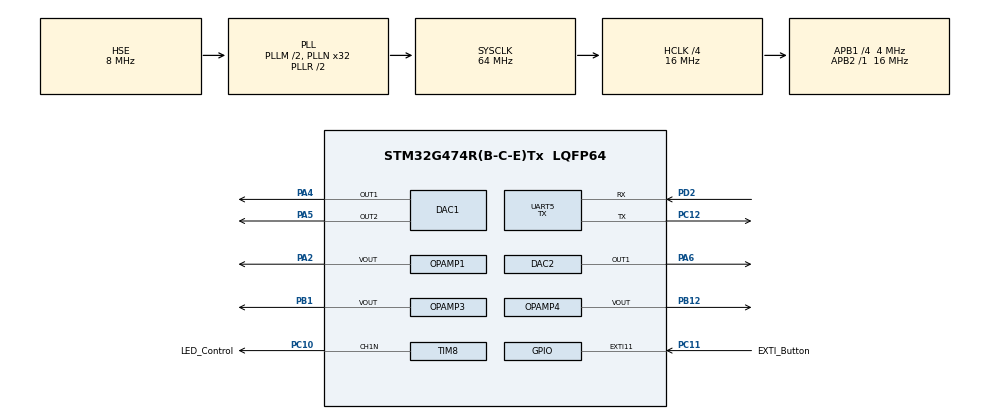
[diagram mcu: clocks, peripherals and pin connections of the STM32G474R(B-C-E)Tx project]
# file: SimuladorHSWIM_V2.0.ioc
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DAC1.DAC_Channel-DAC_OUT2=DAC_CHANNEL_2
DAC1.DAC_Trigger2_OUT1-DAC_OUT1=DAC_TRIGGER_NONE
DAC1.DAC_Trigger2_OUT2-DAC_OUT2=DAC_TRIGGER_NONE
DAC1.DAC_Trigger_OUT1-DAC_OUT1=DAC_TRIGGER_T2_TRGO
DAC1.DAC_Trigger_OUT2-DAC_OUT2=DAC_TRIGGER_T2_TRGO
DAC2.DAC_Trigger_OUT1-DAC_OUT1=DAC_TRIGGER_T2_TRGO
DAC3.DAC_Channel-DAC_OUT2_Int=DAC_CHANNEL_2
DAC3.DAC_Trigger_OUT1-DAC_OUT1_Int=DAC_TRIGGER_T2_TRGO
DAC3.DAC_Trigger_OUT2-DAC_OUT2_Int=DAC_TRIGGER_T2_TRGO
DAC4.DAC_Trigger_OUT1-DAC_OUT1_Int=DAC_TRIGGER_T2_TRGO
Dma.DAC1_CH1.0.Direction=DMA_MEMORY_TO_PERIPH
Dma.DAC1_CH1.0.EventEnable=DISABLE
Dma.DAC1_CH1.0.Instance=DMA1_Channel1
Dma.DAC1_CH1.0.MemDataAlignment=DMA_MDATAALIGN_WORD
Dma.DAC1_CH1.0.MemInc=DMA_MINC_ENABLE
Dma.DAC1_CH1.0.Mode=DMA_NORMAL
Dma.DAC1_CH1.0.PeriphDataAlignment=DMA_PDATAALIGN_WORD
Dma.DAC1_CH1.0.PeriphInc=DMA_PINC_DISABLE
Dma.DAC1_CH1.0.Polarity=HAL_DMAMUX_REQ_GEN_RISING
Dma.DAC1_CH1.0.Priority=DMA_PRIORITY_LOW
Dma.DAC1_CH1.0.RequestNumber=1
Dma.DAC1_CH1.0.SignalID=NONE
Dma.DAC1_CH1.0.SyncEnable=DISABLE
Dma.DAC1_CH1.0.SyncPolarity=HAL_DMAMUX_SYNC_NO_EVENT
Dma.DAC1_CH1.0.SyncRequestNumber=1
Dma.DAC1_CH1.0.SyncSignalID=NONE
Dma.DAC1_CH2.1.Direction=DMA_MEMORY_TO_PERIPH
Dma.DAC1_CH2.1.EventEnable=DISABLE
Dma.DAC1_CH2.1.Instance=DMA1_Channel2
Dma.DAC1_CH2.1.MemDataAlignment=DMA_MDATAALIGN_WORD
Dma.DAC1_CH2.1.MemInc=DMA_MINC_ENABLE
Dma.DAC1_CH2.1.Mode=DMA_NORMAL
Dma.DAC1_CH2.1.PeriphDataAlignment=DMA_PDATAALIGN_WORD
Dma.DAC1_CH2.1.PeriphInc=DMA_PINC_DISABLE
Dma.DAC1_CH2.1.Polarity=HAL_DMAMUX_REQ_GEN_RISING
Dma.DAC1_CH2.1.Priority=DMA_PRIORITY_LOW
Dma.DAC1_CH2.1.RequestNumber=1
Dma.DAC1_CH2.1.SignalID=NONE
Dma.DAC1_CH2.1.SyncEnable=DISABLE
Dma.DAC1_CH2.1.SyncPolarity=HAL_DMAMUX_SYNC_NO_EVENT
Dma.DAC1_CH2.1.SyncRequestNumber=1
Dma.DAC1_CH2.1.SyncSignalID=NONE
Dma.DAC2_CH1.2.Direction=DMA_MEMORY_TO_PERIPH
Dma.DAC2_CH1.2.EventEnable=DISABLE
Dma.DAC2_CH1.2.Instance=DMA1_Channel3
Dma.DAC2_CH1.2.MemDataAlignment=DMA_MDATAALIGN_WORD
Dma.DAC2_CH1.2.MemInc=DMA_MINC_ENABLE
Dma.DAC2_CH1.2.Mode=DMA_NORMAL
Dma.DAC2_CH1.2.PeriphDataAlignment=DMA_PDATAALIGN_WORD
Dma.DAC2_CH1.2.PeriphInc=DMA_PINC_DISABLE
Dma.DAC2_CH1.2.Polarity=HAL_DMAMUX_REQ_GEN_RISING
Dma.DAC2_CH1.2.Priority=DMA_PRIORITY_LOW
Dma.DAC2_CH1.2.RequestNumber=1
Dma.DAC2_CH1.2.SignalID=NONE
Dma.DAC2_CH1.2.SyncEnable=DISABLE
Dma.DAC2_CH1.2.SyncPolarity=HAL_DMAMUX_SYNC_NO_EVENT
Dma.DAC2_CH1.2.SyncRequestNumber=1
Dma.DAC2_CH1.2.SyncSignalID=NONE
Dma.DAC3_CH1.3.Direction=DMA_MEMORY_TO_PERIPH
Dma.DAC3_CH1.3.EventEnable=DISABLE
Dma.DAC3_CH1.3.Instance=DMA1_Channel4
Dma.DAC3_CH1.3.MemDataAlignment=DMA_MDATAALIGN_WORD
Dma.DAC3_CH1.3.MemInc=DMA_MINC_ENABLE
Dma.DAC3_CH1.3.Mode=DMA_NORMAL
Dma.DAC3_CH1.3.PeriphDataAlignment=DMA_PDATAALIGN_WORD
Dma.DAC3_CH1.3.PeriphInc=DMA_PINC_DISABLE
Dma.DAC3_CH1.3.Polarity=HAL_DMAMUX_REQ_GEN_RISING
Dma.DAC3_CH1.3.Priority=DMA_PRIORITY_LOW
Dma.DAC3_CH1.3.RequestNumber=1
Dma.DAC3_CH1.3.SignalID=NONE
Dma.DAC3_CH1.3.SyncEnable=DISABLE
Dma.DAC3_CH1.3.SyncPolarity=HAL_DMAMUX_SYNC_NO_EVENT
Dma.DAC3_CH1.3.SyncRequestNumber=1
Dma.DAC3_CH1.3.SyncSignalID=NONE
Dma.DAC3_CH2.4.Direction=DMA_MEMORY_TO_PERIPH
Dma.DAC3_CH2.4.EventEnable=DISABLE
Dma.DAC3_CH2.4.Instance=DMA1_Channel5
Dma.DAC3_CH2.4.MemDataAlignment=DMA_MDATAALIGN_WORD
Dma.DAC3_CH2.4.MemInc=DMA_MINC_ENABLE
Dma.DAC3_CH2.4.Mode=DMA_NORMAL
Dma.DAC3_CH2.4.PeriphDataAlignment=DMA_PDATAALIGN_WORD
Dma.DAC3_CH2.4.PeriphInc=DMA_PINC_DISABLE
Dma.DAC3_CH2.4.Polarity=HAL_DMAMUX_REQ_GEN_RISING
Dma.DAC3_CH2.4.Priority=DMA_PRIORITY_LOW
Dma.DAC3_CH2.4.RequestNumber=1
Dma.DAC3_CH2.4.SignalID=NONE
Dma.DAC3_CH2.4.SyncEnable=DISABLE
Dma.DAC3_CH2.4.SyncPolarity=HAL_DMAMUX_SYNC_NO_EVENT
Dma.DAC3_CH2.4.SyncRequestNumber=1
Dma.DAC3_CH2.4.SyncSignalID=NONE
Dma.DAC4_CH1.5.Direction=DMA_MEMORY_TO_PERIPH
Dma.DAC4_CH1.5.EventEnable=DISABLE
Dma.DAC4_CH1.5.Instance=DMA1_Channel6
Dma.DAC4_CH1.5.MemDataAlignment=DMA_MDATAALIGN_WORD
Dma.DAC4_CH1.5.MemInc=DMA_MINC_ENABLE
Dma.DAC4_CH1.5.Mode=DMA_NORMAL
Dma.DAC4_CH1.5.PeriphDataAlignment=DMA_PDATAALIGN_WORD
Dma.DAC4_CH1.5.PeriphInc=DMA_PINC_DISABLE
Dma.DAC4_CH1.5.Polarity=HAL_DMAMUX_REQ_GEN_RISING
Dma.DAC4_CH1.5.Priority=DMA_PRIORITY_LOW
Dma.DAC4_CH1.5.RequestNumber=1
Dma.DAC4_CH1.5.SignalID=NONE
Dma.DAC4_CH1.5.SyncEnable=DISABLE
Dma.DAC4_CH1.5.SyncPolarity=HAL_DMAMUX_SYNC_NO_EVENT
Dma.DAC4_CH1.5.SyncRequestNumber=1
Dma.DAC4_CH1.5.SyncSignalID=NONE
Dma.Request0=DAC1_CH1
Dma.Request1=DAC1_CH2
Dma.Request2=DAC2_CH1
Dma.Request3=DAC3_CH1
Dma.Request4=DAC3_CH2
Dma.Request5=DAC4_CH1
Mcu.Family=STM32G4
Mcu.Name=STM32G474R(B-C-E)Tx
Mcu.Package=LQFP64
NVIC.DMA1_Channel1_IRQn=true\:0\:0\:false\:false\:true\:false\:true\:true
NVIC.DMA1_Channel2_IRQn=true\:0\:0\:false\:false\:true\:false\:true\:true
NVIC.DMA1_Channel3_IRQn=true\:0\:0\:false\:false\:true\:false\:true\:true
NVIC.DMA1_Channel4_IRQn=true\:0\:0\:false\:false\:true\:false\:true\:true
NVIC.DMA1_Channel5_IRQn=true\:0\:0\:false\:false\:true\:false\:true\:true
NVIC.DMA1_Channel6_IRQn=true\:0\:0\:false\:false\:true\:false\:true\:true
NVIC.EXTI15_10_IRQn=true\:0\:0\:false\:false\:true\:true\:true\:true
NVIC.PriorityGroup=NVIC_PRIORITYGROUP_4
NVIC.TIM3_IRQn=true\:0\:0\:false\:false\:true\:true\:true\:true
OPAMP1.PowerMode=OPAMP_POWERMODE_HIGHSPEED
OPAMP3.PowerMode=OPAMP_POWERMODE_HIGHSPEED
OPAMP4.PowerMode=OPAMP_POWERMODE_HIGHSPEED
PA13.Mode=Trace_Asynchronous_SW
PA13.Signal=SYS_JTMS-SWDIO
PA14.Mode=Trace_Asynchronous_SW
PA14.Signal=SYS_JTCK-SWCLK
PA2.Signal=SharedAnalog_PA2
PA4.Signal=COMP_DAC11_group
PA5.Signal=COMP_DAC12_group
PA6.Signal=COMP_DAC21_group
PB1.Signal=SharedAnalog_PB1
PB12.Signal=SharedAnalog_PB12
PB3.Mode=Trace_Asynchronous_SW
PB3.Signal=SYS_JTDO-SWO
PC10.GPIO_Label=LED_Control
PC10.Mode=PWM Generation1 CH1N
PC10.Signal=TIM8_CH1N
PC11.GPIO_Label=EXTI_Button
PC11.GPIO_PuPd=GPIO_PULLDOWN
PC11.Signal=GPXTI11
PC12.Mode=Asynchronous
PC12.Signal=UART5_TX
PD2.Mode=Asynchronous
PD2.Signal=UART5_RX
PF0-OSC_IN.Mode=HSE-External-Oscillator
PF0-OSC_IN.Signal=RCC_OSC_IN
PF1-OSC_OUT.Mode=HSE-External-Oscillator
PF1-OSC_OUT.Signal=RCC_OSC_OUT
ProjectManager.HeapSize=0x200
ProjectManager.StackSize=0x400
ProjectManager.TargetToolchain=STM32CubeIDE
RCC.ADC12Freq_Value=64000000
RCC.ADC345Freq_Value=64000000
RCC.AHBCLKDivider=RCC_SYSCLK_DIV4
RCC.AHBFreq_Value=16000000
RCC.APB1CLKDivider=RCC_HCLK_DIV4
RCC.APB1Freq_Value=4000000
RCC.APB1TimFreq_Value=8000000
RCC.APB2Freq_Value=16000000
RCC.APB2TimFreq_Value=16000000
RCC.CortexFreq_Value=16000000
RCC.EXTERNAL_CLOCK_VALUE=12288000
RCC.HCLKFreq_Value=16000000
RCC.HSE_VALUE=8000000
RCC.HSI48_VALUE=48000000
RCC.HSI_VALUE=16000000
RCC.LSE_VALUE=32768
RCC.PLLM=RCC_PLLM_DIV2
RCC.PLLN=32
RCC.PLLSourceVirtual=RCC_PLLSOURCE_HSE
RCC.PREFETCH_ENABLE=1
RCC.PWREXT_OverDrive=PWREXT_OverDrive_DESACTIVATED
RCC.PWR_Regulator_Voltage_Scale=PWR_REGULATOR_VOLTAGE_SCALE1
RCC.RCC_TIM_PRescaler_Selection=RCC_TIMPRES_DESACTIVATED
RCC.SYSCLKFreq_VALUE=64000000
RCC.SYSCLKSource=RCC_SYSCLKSOURCE_PLLCLK
RCC.USBFreq_Value=64000000
RCC.VCOOutputFreq_Value=128000000
SH.COMP_DAC11_group.0=DAC1_OUT1,DAC_OUT1
SH.COMP_DAC12_group.0=DAC1_OUT2,DAC_OUT2
SH.COMP_DAC21_group.0=DAC2_OUT1,DAC_OUT1
SH.SharedAnalog_PA2.0=GPIO_Analog
SH.SharedAnalog_PA2.1=OPAMP1_VOUT,Follower-DAC_OUT2-INP
SH.SharedAnalog_PB1.0=GPIO_Analog
SH.SharedAnalog_PB1.1=OPAMP3_VOUT,Follower-DAC_OUT2-INP
SH.SharedAnalog_PB12.0=GPIO_Analog
SH.SharedAnalog_PB12.1=OPAMP4_VOUT,Follower-DAC_OUT2-INP
TIM2.PeriodNoDither=52.0833-1
TIM2.Prescaler=32-1
TIM2.TIM_MasterOutputTrigger=TIM_TRGO_UPDATE
TIM3.PeriodNoDither=3000-1
TIM3.Prescaler=16000-1
TIM8.BreakPolarity=TIM_BREAKPOLARITY_LOW
TIM8.Channel-PWM\ Generation1\ CH1N=TIM_CHANNEL_1
TIM8.OC1Preload_PWM=DISABLE
TIM8.OCMode_PWM-PWM\ Generation1\ CH1N=TIM_OCMODE_PWM1
TIM8.OCNPolarity_1=TIM_OCNPOLARITY_LOW
TIM8.PeriodNoDither=100
TIM8.Prescaler=16000
TIM8.PulseNoDither_1=50
TIM8.TIM_MasterOutputTrigger=TIM_TRGO_RESET
TIM8.TIM_MasterOutputTrigger2=TIM_TRGO2_RESET
UART5.Mode=MODE_TX
VP_DAC3_VS_DACI1.Mode=DAC_OUT1_Int
VP_DAC3_VS_DACI2.Mode=DAC_OUT2_Int
VP_DAC4_VS_DACI1.Mode=DAC_OUT1_Int
VP_SYS_VS_DBSignals.Mode=DisableDeadBatterySignals
VP_TIM2_VS_ClockSourceINT.Mode=Internal
VP_TIM3_VS_ClockSourceINT.Mode=Internal
VP_TIM8_VS_OPM.Mode=OPM_bit
board=custom

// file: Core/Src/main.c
/* USER CODE BEGIN Header */
/**
  ******************************************************************************
  * @file           : main.c
  * @brief          : Main program body
  ******************************************************************************
  * @attention
  *
  * Copyright (c) 2024 STMicroelectronics.
  * All rights reserved.
  *
  * This software is licensed under terms that can be found in the LICENSE file
  * in the root directory of this software component.
  * If no LICENSE file comes with this software, it is provided AS-IS.
  *
  ******************************************************************************
  */
/* USER CODE END Header */
#include "main.h"

/* USER CODE BEGIN Includes */
#include "DACSim.h"
/* USER CODE END Includes */

DAC_HandleTypeDef hdac1;
DAC_HandleTypeDef hdac2;
DAC_HandleTypeDef hdac3;
DAC_HandleTypeDef hdac4;
DMA_HandleTypeDef hdma_dac1_ch1;
DMA_HandleTypeDef hdma_dac1_ch2;
DMA_HandleTypeDef hdma_dac2_ch1;
DMA_HandleTypeDef hdma_dac3_ch1;
DMA_HandleTypeDef hdma_dac3_ch2;
DMA_HandleTypeDef hdma_dac4_ch1;

OPAMP_HandleTypeDef hopamp1;
OPAMP_HandleTypeDef hopamp3;
OPAMP_HandleTypeDef hopamp4;

TIM_HandleTypeDef htim2;
TIM_HandleTypeDef htim3;
TIM_HandleTypeDef htim8;

UART_HandleTypeDef huart5;

void SystemClock_Config(void);
static void MX_GPIO_Init(void);
static void MX_DMA_Init(void);
static void MX_DAC1_Init(void);
static void MX_DAC2_Init(void);
static void MX_DAC3_Init(void);
static void MX_OPAMP1_Init(void);
static void MX_OPAMP3_Init(void);
static void MX_TIM2_Init(void);
static void MX_DAC4_Init(void);
static void MX_OPAMP4_Init(void);
static void MX_TIM3_Init(void);
static void MX_UART5_Init(void);
static void MX_TIM8_Init(void);

int main(void)
{

  /* MCU Configuration--------------------------------------------------------*/

  /* Reset of all peripherals, Initializes the Flash interface and the Systick. */
  HAL_Init();

  /* Configure the system clock */
  SystemClock_Config();

  /* Initialize all configured peripherals */
  MX_GPIO_Init();
  MX_DMA_Init();
  MX_DAC1_Init();
  MX_DAC2_Init();
  MX_DAC3_Init();
  MX_OPAMP1_Init();
  MX_OPAMP3_Init();
  MX_TIM2_Init();
  MX_DAC4_Init();
  MX_OPAMP4_Init();
  MX_TIM3_Init();
  MX_UART5_Init();
  MX_TIM8_Init();
  /* USER CODE BEGIN 2 */

  SysInit();
  /* USER CODE END 2 */

  /* Infinite loop */
  while (1)
  {

    /* USER CODE BEGIN 3 */

	  LoopMain();
  }
  /* USER CODE END 3 */
}

void SystemClock_Config(void)
{
  RCC_OscInitTypeDef RCC_OscInitStruct = {0};
  RCC_ClkInitTypeDef RCC_ClkInitStruct = {0};

  /** Configure the main internal regulator output voltage
  */
  HAL_PWREx_ControlVoltageScaling(PWR_REGULATOR_VOLTAGE_SCALE1);

  /** Initializes the RCC Oscillators according to the specified parameters
  * in the RCC_OscInitTypeDef structure.
  */
  RCC_OscInitStruct.OscillatorType = RCC_OSCILLATORTYPE_HSE;
  RCC_OscInitStruct.HSEState = RCC_HSE_ON;
  RCC_OscInitStruct.PLL.PLLState = RCC_PLL_ON;
  RCC_OscInitStruct.PLL.PLLSource = RCC_PLLSOURCE_HSE;
  RCC_OscInitStruct.PLL.PLLM = RCC_PLLM_DIV2;
  RCC_OscInitStruct.PLL.PLLN = 32;
  RCC_OscInitStruct.PLL.PLLP = RCC_PLLP_DIV2;
  RCC_OscInitStruct.PLL.PLLQ = RCC_PLLQ_DIV2;
  RCC_OscInitStruct.PLL.PLLR = RCC_PLLR_DIV2;
  if (HAL_RCC_OscConfig(&RCC_OscInitStruct) != HAL_OK)
  {
    Error_Handler();
  }

  /** Initializes the CPU, AHB and APB buses clocks
  */
  RCC_ClkInitStruct.ClockType = RCC_CLOCKTYPE_HCLK|RCC_CLOCKTYPE_SYSCLK
                              |RCC_CLOCKTYPE_PCLK1|RCC_CLOCKTYPE_PCLK2;
  RCC_ClkInitStruct.SYSCLKSource = RCC_SYSCLKSOURCE_PLLCLK;
  RCC_ClkInitStruct.AHBCLKDivider = RCC_SYSCLK_DIV4;
  RCC_ClkInitStruct.APB1CLKDivider = RCC_HCLK_DIV4;
  RCC_ClkInitStruct.APB2CLKDivider = RCC_HCLK_DIV1;

  if (HAL_RCC_ClockConfig(&RCC_ClkInitStruct, FLASH_LATENCY_0) != HAL_OK)
  {
    Error_Handler();
  }
}

static void MX_DAC1_Init(void)
{

  DAC_ChannelConfTypeDef sConfig = {0};

  /** DAC Initialization
  */
  hdac1.Instance = DAC1;
  if (HAL_DAC_Init(&hdac1) != HAL_OK)
  {
    Error_Handler();
  }

  /** DAC channel OUT1 config
  */
  sConfig.DAC_HighFrequency = DAC_HIGH_FREQUENCY_INTERFACE_MODE_AUTOMATIC;
  sConfig.DAC_DMADoubleDataMode = DISABLE;
  sConfig.DAC_SignedFormat = DISABLE;
  sConfig.DAC_SampleAndHold = DAC_SAMPLEANDHOLD_DISABLE;
  sConfig.DAC_Trigger = DAC_TRIGGER_T2_TRGO;
  sConfig.DAC_Trigger2 = DAC_TRIGGER_NONE;
  sConfig.DAC_OutputBuffer = DAC_OUTPUTBUFFER_ENABLE;
  sConfig.DAC_ConnectOnChipPeripheral = DAC_CHIPCONNECT_EXTERNAL;
  sConfig.DAC_UserTrimming = DAC_TRIMMING_FACTORY;
  if (HAL_DAC_ConfigChannel(&hdac1, &sConfig, DAC_CHANNEL_1) != HAL_OK)
  {
    Error_Handler();
  }

  /** DAC channel OUT2 config
  */
  if (HAL_DAC_ConfigChannel(&hdac1, &sConfig, DAC_CHANNEL_2) != HAL_OK)
  {
    Error_Handler();
  }

}

static void MX_DAC2_Init(void)
{

  DAC_ChannelConfTypeDef sConfig = {0};

  /** DAC Initialization
  */
  hdac2.Instance = DAC2;
  if (HAL_DAC_Init(&hdac2) != HAL_OK)
  {
    Error_Handler();
  }

  /** DAC channel OUT1 config
  */
  sConfig.DAC_HighFrequency = DAC_HIGH_FREQUENCY_INTERFACE_MODE_AUTOMATIC;
  sConfig.DAC_DMADoubleDataMode = DISABLE;
  sConfig.DAC_SignedFormat = DISABLE;
  sConfig.DAC_SampleAndHold = DAC_SAMPLEANDHOLD_DISABLE;
  sConfig.DAC_Trigger = DAC_TRIGGER_T2_TRGO;
  sConfig.DAC_Trigger2 = DAC_TRIGGER_NONE;
  sConfig.DAC_OutputBuffer = DAC_OUTPUTBUFFER_ENABLE;
  sConfig.DAC_ConnectOnChipPeripheral = DAC_CHIPCONNECT_EXTERNAL;
  sConfig.DAC_UserTrimming = DAC_TRIMMING_FACTORY;
  if (HAL_DAC_ConfigChannel(&hdac2, &sConfig, DAC_CHANNEL_1) != HAL_OK)
  {
    Error_Handler();
  }

}

static void MX_DAC3_Init(void)
{

  DAC_ChannelConfTypeDef sConfig = {0};

  /** DAC Initialization
  */
  hdac3.Instance = DAC3;
  if (HAL_DAC_Init(&hdac3) != HAL_OK)
  {
    Error_Handler();
  }

  /** DAC channel OUT1 config
  */
  sConfig.DAC_HighFrequency = DAC_HIGH_FREQUENCY_INTERFACE_MODE_AUTOMATIC;
  sConfig.DAC_DMADoubleDataMode = DISABLE;
  sConfig.DAC_SignedFormat = DISABLE;
  sConfig.DAC_SampleAndHold = DAC_SAMPLEANDHOLD_DISABLE;
  sConfig.DAC_Trigger = DAC_TRIGGER_T2_TRGO;
  sConfig.DAC_Trigger2 = DAC_TRIGGER_NONE;
  sConfig.DAC_OutputBuffer = DAC_OUTPUTBUFFER_DISABLE;
  sConfig.DAC_ConnectOnChipPeripheral = DAC_CHIPCONNECT_INTERNAL;
  sConfig.DAC_UserTrimming = DAC_TRIMMING_FACTORY;
  if (HAL_DAC_ConfigChannel(&hdac3, &sConfig, DAC_CHANNEL_1) != HAL_OK)
  {
    Error_Handler();
  }

  /** DAC channel OUT2 config
  */
  if (HAL_DAC_ConfigChannel(&hdac3, &sConfig, DAC_CHANNEL_2) != HAL_OK)
  {
    Error_Handler();
  }

}

static void MX_DAC4_Init(void)
{

  DAC_ChannelConfTypeDef sConfig = {0};

  /** DAC Initialization
  */
  hdac4.Instance = DAC4;
  if (HAL_DAC_Init(&hdac4) != HAL_OK)
  {
    Error_Handler();
  }

  /** DAC channel OUT1 config
  */
  sConfig.DAC_HighFrequency = DAC_HIGH_FREQUENCY_INTERFACE_MODE_AUTOMATIC;
  sConfig.DAC_DMADoubleDataMode = DISABLE;
  sConfig.DAC_SignedFormat = DISABLE;
  sConfig.DAC_SampleAndHold = DAC_SAMPLEANDHOLD_DISABLE;
  sConfig.DAC_Trigger = DAC_TRIGGER_T2_TRGO;
  sConfig.DAC_Trigger2 = DAC_TRIGGER_NONE;
  sConfig.DAC_OutputBuffer = DAC_OUTPUTBUFFER_DISABLE;
  sConfig.DAC_ConnectOnChipPeripheral = DAC_CHIPCONNECT_INTERNAL;
  sConfig.DAC_UserTrimming = DAC_TRIMMING_FACTORY;
  if (HAL_DAC_ConfigChannel(&hdac4, &sConfig, DAC_CHANNEL_1) != HAL_OK)
  {
    Error_Handler();
  }

}

static void MX_OPAMP1_Init(void)
{

  hopamp1.Instance = OPAMP1;
  hopamp1.Init.PowerMode = OPAMP_POWERMODE_HIGHSPEED;
  hopamp1.Init.Mode = OPAMP_FOLLOWER_MODE;
  hopamp1.Init.NonInvertingInput = OPAMP_NONINVERTINGINPUT_DAC;
  hopamp1.Init.InternalOutput = DISABLE;
  hopamp1.Init.TimerControlledMuxmode = OPAMP_TIMERCONTROLLEDMUXMODE_DISABLE;
  hopamp1.Init.UserTrimming = OPAMP_TRIMMING_FACTORY;
  if (HAL_OPAMP_Init(&hopamp1) != HAL_OK)
  {
    Error_Handler();
  }

}

static void MX_OPAMP3_Init(void)
{

  hopamp3.Instance = OPAMP3;
  hopamp3.Init.PowerMode = OPAMP_POWERMODE_HIGHSPEED;
  hopamp3.Init.Mode = OPAMP_FOLLOWER_MODE;
  hopamp3.Init.NonInvertingInput = OPAMP_NONINVERTINGINPUT_DAC;
  hopamp3.Init.InternalOutput = DISABLE;
  hopamp3.Init.TimerControlledMuxmode = OPAMP_TIMERCONTROLLEDMUXMODE_DISABLE;
  hopamp3.Init.UserTrimming = OPAMP_TRIMMING_FACTORY;
  if (HAL_OPAMP_Init(&hopamp3) != HAL_OK)
  {
    Error_Handler();
  }

}

static void MX_OPAMP4_Init(void)
{

  hopamp4.Instance = OPAMP4;
  hopamp4.Init.PowerMode = OPAMP_POWERMODE_HIGHSPEED;
  hopamp4.Init.Mode = OPAMP_FOLLOWER_MODE;
  hopamp4.Init.NonInvertingInput = OPAMP_NONINVERTINGINPUT_DAC;
  hopamp4.Init.InternalOutput = DISABLE;
  hopamp4.Init.TimerControlledMuxmode = OPAMP_TIMERCONTROLLEDMUXMODE_DISABLE;
  hopamp4.Init.UserTrimming = OPAMP_TRIMMING_FACTORY;
  if (HAL_OPAMP_Init(&hopamp4) != HAL_OK)
  {
    Error_Handler();
  }

}

static void MX_TIM2_Init(void)
{

  TIM_ClockConfigTypeDef sClockSourceConfig = {0};
  TIM_MasterConfigTypeDef sMasterConfig = {0};

  htim2.Instance = TIM2;
  htim2.Init.Prescaler = 32-1;
  htim2.Init.CounterMode = TIM_COUNTERMODE_UP;
  htim2.Init.Period = 51;
  htim2.Init.ClockDivision = TIM_CLOCKDIVISION_DIV1;
  htim2.Init.AutoReloadPreload = TIM_AUTORELOAD_PRELOAD_DISABLE;
  if (HAL_TIM_Base_Init(&htim2) != HAL_OK)
  {
    Error_Handler();
  }
  sClockSourceConfig.ClockSource = TIM_CLOCKSOURCE_INTERNAL;
  if (HAL_TIM_ConfigClockSource(&htim2, &sClockSourceConfig) != HAL_OK)
  {
    Error_Handler();
  }
  sMasterConfig.MasterOutputTrigger = TIM_TRGO_UPDATE;
  sMasterConfig.MasterSlaveMode = TIM_MASTERSLAVEMODE_DISABLE;
  if (HAL_TIMEx_MasterConfigSynchronization(&htim2, &sMasterConfig) != HAL_OK)
  {
    Error_Handler();
  }

}

static void MX_TIM3_Init(void)
{

  TIM_ClockConfigTypeDef sClockSourceConfig = {0};
  TIM_MasterConfigTypeDef sMasterConfig = {0};

  htim3.Instance = TIM3;
  htim3.Init.Prescaler = 16000-1;
  htim3.Init.CounterMode = TIM_COUNTERMODE_UP;
  htim3.Init.Period = 2999;
  htim3.Init.ClockDivision = TIM_CLOCKDIVISION_DIV1;
  htim3.Init.AutoReloadPreload = TIM_AUTORELOAD_PRELOAD_DISABLE;
  if (HAL_TIM_Base_Init(&htim3) != HAL_OK)
  {
    Error_Handler();
  }
  sClockSourceConfig.ClockSource = TIM_CLOCKSOURCE_INTERNAL;
  if (HAL_TIM_ConfigClockSource(&htim3, &sClockSourceConfig) != HAL_OK)
  {
    Error_Handler();
  }
  sMasterConfig.MasterOutputTrigger = TIM_TRGO_RESET;
  sMasterConfig.MasterSlaveMode = TIM_MASTERSLAVEMODE_DISABLE;
  if (HAL_TIMEx_MasterConfigSynchronization(&htim3, &sMasterConfig) != HAL_OK)
  {
    Error_Handler();
  }

}

static void MX_TIM8_Init(void)
{

  TIM_MasterConfigTypeDef sMasterConfig = {0};
  TIM_OC_InitTypeDef sConfigOC = {0};
  TIM_BreakDeadTimeConfigTypeDef sBreakDeadTimeConfig = {0};

  htim8.Instance = TIM8;
  htim8.Init.Prescaler = 16000;
  htim8.Init.CounterMode = TIM_COUNTERMODE_UP;
  htim8.Init.Period = 100;
  htim8.Init.ClockDivision = TIM_CLOCKDIVISION_DIV1;
  htim8.Init.RepetitionCounter = 0;
  htim8.Init.AutoReloadPreload = TIM_AUTORELOAD_PRELOAD_DISABLE;
  if (HAL_TIM_PWM_Init(&htim8) != HAL_OK)
  {
    Error_Handler();
  }
  if (HAL_TIM_OnePulse_Init(&htim8, TIM_OPMODE_SINGLE) != HAL_OK)
  {
    Error_Handler();
  }
  sMasterConfig.MasterOutputTrigger = TIM_TRGO_RESET;
  sMasterConfig.MasterOutputTrigger2 = TIM_TRGO2_RESET;
  sMasterConfig.MasterSlaveMode = TIM_MASTERSLAVEMODE_DISABLE;
  if (HAL_TIMEx_MasterConfigSynchronization(&htim8, &sMasterConfig) != HAL_OK)
  {
    Error_Handler();
  }
  sConfigOC.OCMode = TIM_OCMODE_PWM1;
  sConfigOC.Pulse = 50;
  sConfigOC.OCPolarity = TIM_OCPOLARITY_HIGH;
  sConfigOC.OCNPolarity = TIM_OCNPOLARITY_LOW;
  sConfigOC.OCFastMode = TIM_OCFAST_DISABLE;
  sConfigOC.OCIdleState = TIM_OCIDLESTATE_RESET;
  sConfigOC.OCNIdleState = TIM_OCNIDLESTATE_RESET;
  if (HAL_TIM_PWM_ConfigChannel(&htim8, &sConfigOC, TIM_CHANNEL_1) != HAL_OK)
  {
    Error_Handler();
  }
  __HAL_TIM_DISABLE_OCxPRELOAD(&htim8, TIM_CHANNEL_1);
  sBreakDeadTimeConfig.OffStateRunMode = TIM_OSSR_DISABLE;
  sBreakDeadTimeConfig.OffStateIDLEMode = TIM_OSSI_DISABLE;
  sBreakDeadTimeConfig.LockLevel = TIM_LOCKLEVEL_OFF;
  sBreakDeadTimeConfig.DeadTime = 0;
  sBreakDeadTimeConfig.BreakState = TIM_BREAK_DISABLE;
  sBreakDeadTimeConfig.BreakPolarity = TIM_BREAKPOLARITY_LOW;
  sBreakDeadTimeConfig.BreakFilter = 0;
  sBreakDeadTimeConfig.BreakAFMode = TIM_BREAK_AFMODE_INPUT;
  sBreakDeadTimeConfig.Break2State = TIM_BREAK2_DISABLE;
  sBreakDeadTimeConfig.Break2Polarity = TIM_BREAK2POLARITY_HIGH;
  sBreakDeadTimeConfig.Break2Filter = 0;
  sBreakDeadTimeConfig.Break2AFMode = TIM_BREAK_AFMODE_INPUT;
  sBreakDeadTimeConfig.AutomaticOutput = TIM_AUTOMATICOUTPUT_DISABLE;
  if (HAL_TIMEx_ConfigBreakDeadTime(&htim8, &sBreakDeadTimeConfig) != HAL_OK)
  {
    Error_Handler();
  }
  HAL_TIM_MspPostInit(&htim8);

}

static void MX_UART5_Init(void)
{

  huart5.Instance = UART5;
  huart5.Init.BaudRate = 115200;
  huart5.Init.WordLength = UART_WORDLENGTH_8B;
  huart5.Init.StopBits = UART_STOPBITS_1;
  huart5.Init.Parity = UART_PARITY_NONE;
  huart5.Init.Mode = UART_MODE_TX;
  huart5.Init.HwFlowCtl = UART_HWCONTROL_NONE;
  huart5.Init.OverSampling = UART_OVERSAMPLING_16;
  huart5.Init.OneBitSampling = UART_ONE_BIT_SAMPLE_DISABLE;
  huart5.Init.ClockPrescaler = UART_PRESCALER_DIV1;
  huart5.AdvancedInit.AdvFeatureInit = UART_ADVFEATURE_NO_INIT;
  if (HAL_UART_Init(&huart5) != HAL_OK)
  {
    Error_Handler();
  }
  if (HAL_UARTEx_SetTxFifoThreshold(&huart5, UART_TXFIFO_THRESHOLD_1_8) != HAL_OK)
  {
    Error_Handler();
  }
  if (HAL_UARTEx_SetRxFifoThreshold(&huart5, UART_RXFIFO_THRESHOLD_1_8) != HAL_OK)
  {
    Error_Handler();
  }
  if (HAL_UARTEx_DisableFifoMode(&huart5) != HAL_OK)
  {
    Error_Handler();
  }

}

static void MX_DMA_Init(void)
{

  /* DMA controller clock enable */
  __HAL_RCC_DMAMUX1_CLK_ENABLE();
  __HAL_RCC_DMA1_CLK_ENABLE();

  /* DMA interrupt init */
  /* DMA1_Channel1_IRQn interrupt configuration */
  HAL_NVIC_SetPriority(DMA1_Channel1_IRQn, 0, 0);
  HAL_NVIC_EnableIRQ(DMA1_Channel1_IRQn);
  /* DMA1_Channel2_IRQn interrupt configuration */
  HAL_NVIC_SetPriority(DMA1_Channel2_IRQn, 0, 0);
  HAL_NVIC_EnableIRQ(DMA1_Channel2_IRQn);
  /* DMA1_Channel3_IRQn interrupt configuration */
  HAL_NVIC_SetPriority(DMA1_Channel3_IRQn, 0, 0);
  HAL_NVIC_EnableIRQ(DMA1_Channel3_IRQn);
  /* DMA1_Channel4_IRQn interrupt configuration */
  HAL_NVIC_SetPriority(DMA1_Channel4_IRQn, 0, 0);
  HAL_NVIC_EnableIRQ(DMA1_Channel4_IRQn);
  /* DMA1_Channel5_IRQn interrupt configuration */
  HAL_NVIC_SetPriority(DMA1_Channel5_IRQn, 0, 0);
  HAL_NVIC_EnableIRQ(DMA1_Channel5_IRQn);
  /* DMA1_Channel6_IRQn interrupt configuration */
  HAL_NVIC_SetPriority(DMA1_Channel6_IRQn, 0, 0);
  HAL_NVIC_EnableIRQ(DMA1_Channel6_IRQn);

}

static void MX_GPIO_Init(void)
{
  GPIO_InitTypeDef GPIO_InitStruct = {0};

  /* GPIO Ports Clock Enable */
  __HAL_RCC_GPIOF_CLK_ENABLE();
  __HAL_RCC_GPIOA_CLK_ENABLE();
  __HAL_RCC_GPIOB_CLK_ENABLE();
  __HAL_RCC_GPIOC_CLK_ENABLE();
  __HAL_RCC_GPIOD_CLK_ENABLE();

  /*Configure GPIO pin : EXTI_Button_Pin */
  GPIO_InitStruct.Pin = EXTI_Button_Pin;
  GPIO_InitStruct.Mode = GPIO_MODE_IT_RISING;
  GPIO_InitStruct.Pull = GPIO_PULLDOWN;
  HAL_GPIO_Init(EXTI_Button_GPIO_Port, &GPIO_InitStruct);

  /* EXTI interrupt init*/
  HAL_NVIC_SetPriority(EXTI15_10_IRQn, 0, 0);
  HAL_NVIC_EnableIRQ(EXTI15_10_IRQn);

}

void Error_Handler(void)
{
  __disable_irq();
  while (1)
  {
  }
}
